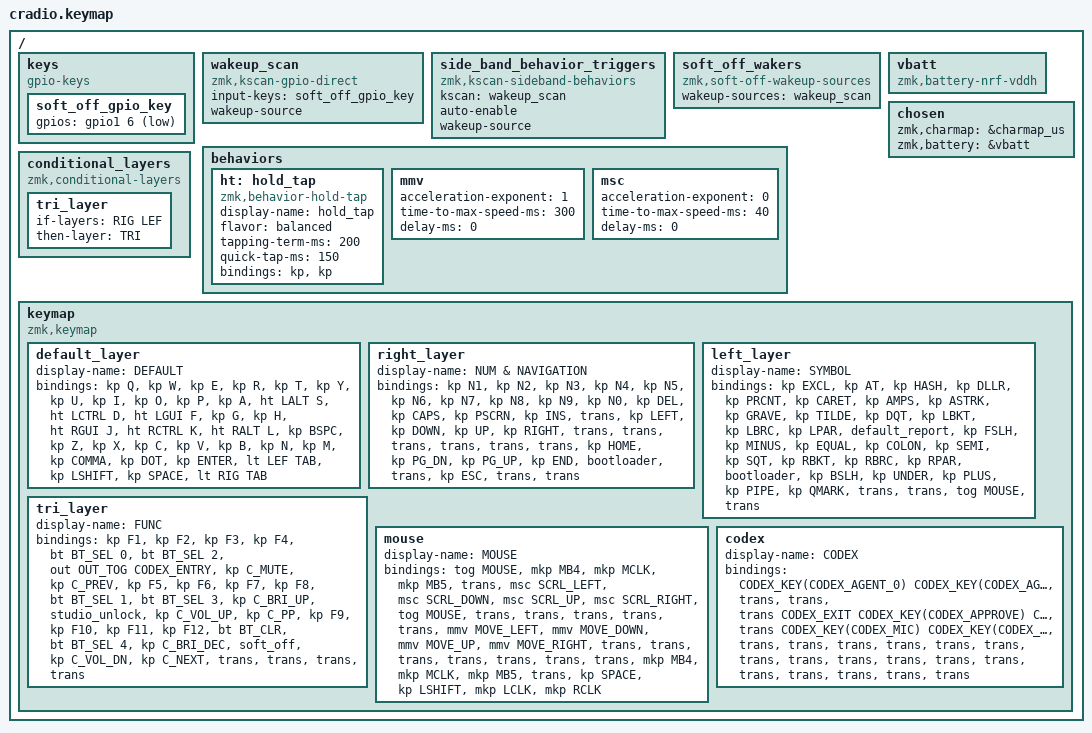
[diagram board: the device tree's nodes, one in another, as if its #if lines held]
// Copyright (c) 2022 The ZMK Contributors
// SPDX-License-Identifier: MIT

#define ZMK_POINTING_DEFAULT_MOVE_VAL 2500  // 600
#define ZMK_POINTING_DEFAULT_SCRL_VAL 20    // 10

#include <behaviors.dtsi>
#include "behaviors/character_map.dtsi"
#include "behaviors/send_string.dtsi"
#include "behaviors/report.dtsi"
#include <dt-bindings/zmk/bt.h>
#include <dt-bindings/zmk/keys.h>
#include <dt-bindings/zmk/outputs.h>
#include <dt-bindings/zmk/pointing.h>
#if defined(NXTKB_CODEX_MICRO)
#include <dt-bindings/nxtkb/codex.h>
#include <behaviors/codex_key.dtsi>
#endif

#define RIG 1
#define LEF 2
#define TRI 3
#define MOUSE 4
#define CODEX 5

#if defined(NXTKB_CODEX_MICRO)
#define CODEX_ENTRY &tog CODEX
#define CODEX_EXIT &tog CODEX
#define CODEX_KEY(n) &codex_key n
#else
#define CODEX_ENTRY &trans
#define CODEX_EXIT &trans
#define CODEX_KEY(n) &trans
#endif


// https://zmk.dev/docs/development/hardware-integration/soft-off-setup?advanced-methods=wakeup&kscan-type=dkscan
/ {
    keys {
        compatible = "gpio-keys";
        soft_off_gpio_key: soft_off_gpio_key {
            gpios = <&gpio1 6 (GPIO_ACTIVE_LOW | GPIO_PULL_UP)>;
        };
    };
    wakeup_scan: wakeup_scan {
        compatible = "zmk,kscan-gpio-direct";
        input-keys = <&soft_off_gpio_key>;
        wakeup-source;
    };
    side_band_behavior_triggers: side_band_behavior_triggers {
        compatible = "zmk,kscan-sideband-behaviors";
        kscan = <&wakeup_scan>;
        auto-enable;
        wakeup-source;
    };
    soft_off_wakers {
        compatible = "zmk,soft-off-wakeup-sources";
        wakeup-sources = <&wakeup_scan>;
    };
};

/ {
    vbatt: vbatt {
        compatible = "zmk,battery-nrf-vddh";
    };
    chosen {
        zmk,charmap = &charmap_us;
        zmk,battery = &vbatt;
    };
    behaviors {
        ht: hold_tap {
            display-name = "hold_tap";
            compatible = "zmk,behavior-hold-tap";
            #binding-cells = <2>;
            flavor = "balanced";
            tapping-term-ms = <200>;
            quick-tap-ms = <150>;
            bindings = <&kp>, <&kp>;
        };
        mmv {
            acceleration-exponent = <1>;      // 1
            time-to-max-speed-ms = <300>;    // 40
            delay-ms = <0>;                   // 0
        };
        msc {
            acceleration-exponent = <0>;      // 0
            time-to-max-speed-ms = <40>;      // 500
            delay-ms = <0>;                   // 10
        };
    };

    conditional_layers {
        compatible = "zmk,conditional-layers";

        tri_layer {
            if-layers = <RIG LEF>;
            then-layer = <TRI>;
        };
    };

    keymap {
        compatible = "zmk,keymap";

        default_layer {
            display-name = "DEFAULT";
            bindings = <
            &kp Q  &kp W       &kp E        &kp R        &kp T         &kp Y      &kp U        &kp I        &kp O       &kp P
            &kp A  &ht LALT S  &ht LCTRL D  &ht LGUI F   &kp G         &kp H      &ht RGUI J   &ht RCTRL K  &ht RALT L  &kp BSPC
            &kp Z  &kp X       &kp C        &kp V        &kp B         &kp N      &kp M        &kp COMMA    &kp DOT     &kp ENTER
            &lt LEF TAB  &kp LSHIFT     &kp SPACE &lt RIG TAB
            >;
        };

        right_layer {
            display-name = "NUM & NAVIGATION";
            bindings = <
            &kp N1   &kp N2    &kp N3     &kp N4   &kp N5     &kp N6  &kp N7    &kp N8     &kp N9     &kp N0
            &kp DEL  &kp CAPS  &kp PSCRN  &kp INS  &trans     &kp LEFT  &kp DOWN   &kp UP  &kp RIGHT &trans
            &trans   &trans    &trans     &trans   &trans     &kp HOME  &kp PG_DN  &kp PG_UP  &kp END &bootloader
            &trans   &kp ESC    &trans  &trans
            >;
        };

        left_layer {
            display-name = "SYMBOL";
            bindings = <
            &kp EXCL  &kp AT    &kp HASH  &kp DLLR  &kp PRCNT    &kp CARET  &kp AMPS   &kp ASTRK  &kp GRAVE  &kp TILDE
            &kp DQT   &kp LBKT  &kp LBRC  &kp LPAR  &default_report       &kp FSLH   &kp MINUS  &kp EQUAL  &kp COLON  &kp SEMI
            &kp SQT   &kp RBKT  &kp RBRC  &kp RPAR  &bootloader       &kp BSLH   &kp UNDER  &kp PLUS   &kp PIPE   &kp QMARK
            &trans    &trans       &tog MOUSE     &trans
            >;
        };

        tri_layer {
            display-name = "FUNC";
            bindings = <
            &kp F1  &kp F2   &kp F3   &kp F4   &bt BT_SEL 0    &bt BT_SEL 2  &out OUT_TOG   CODEX_ENTRY  &kp C_MUTE    &kp C_PREV
            &kp F5  &kp F6   &kp F7   &kp F8   &bt BT_SEL 1    &bt BT_SEL 3  &kp C_BRI_UP   &studio_unlock    &kp C_VOL_UP  &kp C_PP
            &kp F9  &kp F10  &kp F11  &kp F12  &bt BT_CLR      &bt BT_SEL 4  &kp C_BRI_DEC  &soft_off    &kp C_VOL_DN  &kp C_NEXT
            &trans   &trans          &trans        &trans
            >;
        };
        mouse {
            display-name = "MOUSE";
            bindings = <
            &tog MOUSE  &mkp MB4  &mkp MCLK  &mkp MB5   &trans      &msc SCRL_LEFT     &msc SCRL_DOWN    &msc SCRL_UP     &msc SCRL_RIGHT    &tog MOUSE
            &trans      &trans    &trans     &trans     &trans      &mmv MOVE_LEFT     &mmv MOVE_DOWN    &mmv MOVE_UP     &mmv MOVE_RIGHT    &trans
            &trans      &trans    &trans     &trans     &trans      &trans     &mkp MB4  &mkp MCLK  &mkp MB5  &trans
            &kp SPACE  &kp LSHIFT  &mkp LCLK  &mkp RCLK
            >;
        };
#if defined(NXTKB_CODEX_MICRO)
        codex {
            display-name = "CODEX";
            bindings = <
            CODEX_KEY(CODEX_AGENT_0)  CODEX_KEY(CODEX_AGENT_1)  CODEX_KEY(CODEX_AGENT_2)  CODEX_KEY(CODEX_AGENT_3)  CODEX_KEY(CODEX_AGENT_4)  CODEX_KEY(CODEX_AGENT_5)  &trans  &trans  &trans  CODEX_EXIT
            CODEX_KEY(CODEX_APPROVE)  CODEX_KEY(CODEX_SPLIT)  CODEX_KEY(CODEX_DECLINE)  CODEX_KEY(CODEX_FAST)  &trans  CODEX_KEY(CODEX_MIC)  CODEX_KEY(CODEX_SEND)  &trans  &trans  &trans
            &trans  &trans  &trans  &trans  &trans  &trans  &trans  &trans  &trans  &trans
            &trans  &trans  &trans  &trans
            >;
        };
#endif
    };
};
